AUTOSAR XML (schema 3.1.2)
package /Components/SWC_AirSysAir
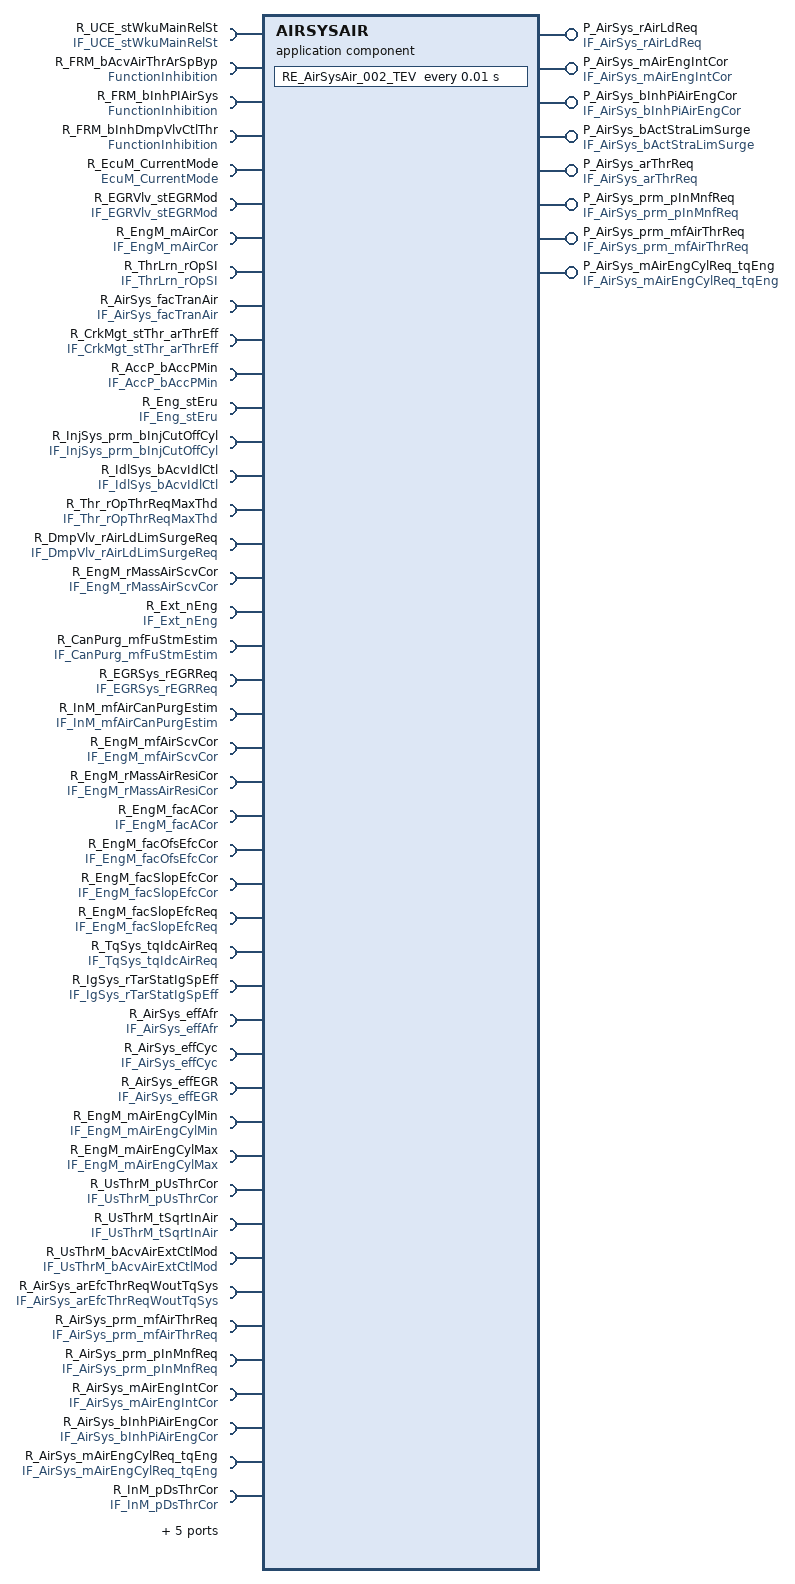
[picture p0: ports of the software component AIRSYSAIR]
  application software component type AIRSYSAIR  # AirSysAir
    4 x require port:
      R_UCE_stWkuMainRelSt: required-interface=IF_UCE_stWkuMainRelSt
      R_FRM_bAcvAirThrArSpByp: required-interface=FunctionInhibition
      R_FRM_bInhPIAirSys: required-interface=FunctionInhibition
      R_FRM_bInhDmpVlvCtlThr: required-interface=FunctionInhibition
    8 x provide port:
      P_AirSys_rAirLdReq: unqueued-sender-com-spec{data-element=AirSys_rAirLdReq, can-invalidate=false, init-value=ConstantValue}, provided-interface=IF_AirSys_rAirLdReq
      P_AirSys_mAirEngIntCor: unqueued-sender-com-spec{data-element=AirSys_mAirEngIntCor, can-invalidate=false, init-value=UInt32InitValue}, provided-interface=IF_AirSys_mAirEngIntCor
      P_AirSys_bInhPiAirEngCor: unqueued-sender-com-spec{data-element=AirSys_bInhPiAirEngCor, can-invalidate=false, init-value=BooleanInitValue}, provided-interface=IF_AirSys_bInhPiAirEngCor
      P_AirSys_bActStraLimSurge: unqueued-sender-com-spec{data-element=AirSys_bActStraLimSurge, can-invalidate=false, init-value=ConstantValue1}, provided-interface=IF_AirSys_bActStraLimSurge
      P_AirSys_arThrReq: unqueued-sender-com-spec{data-element=AirSys_arThrReq, can-invalidate=false, init-value=UInt16InitValue}, provided-interface=IF_AirSys_arThrReq
      P_AirSys_prm_pInMnfReq: unqueued-sender-com-spec{data-element=AirSys_prm_pInMnfReq, can-invalidate=false, init-value=rt_Array_UInt16_2InitValue}, provided-interface=IF_AirSys_prm_pInMnfReq
      P_AirSys_prm_mfAirThrReq: unqueued-sender-com-spec{data-element=AirSys_prm_mfAirThrReq, can-invalidate=false, init-value=rt_Array_UInt16_2InitValue3}, provided-interface=IF_AirSys_prm_mfAirThrReq
      P_AirSys_mAirEngCylReq_tqEng: unqueued-sender-com-spec{data-element=AirSys_mAirEngCylReq_tqEng, can-invalidate=false, init-value=UInt16InitValue5}, provided-interface=IF_AirSys_mAirEngCylReq_tqEng
    45 x require port:
      R_EcuM_CurrentMode: required-interface=EcuM_CurrentMode
      R_EGRVlv_stEGRMod: unqueued-receiver-com-spec{data-element=EGRVlv_stEGRMod, init-value=ConstantValue7, resync-time=0}, required-interface=IF_EGRVlv_stEGRMod
      R_EngM_mAirCor: unqueued-receiver-com-spec{data-element=EngM_mAirCor, init-value=ConstantValue9, resync-time=0}, required-interface=IF_EngM_mAirCor
      R_ThrLrn_rOpSI: unqueued-receiver-com-spec{data-element=ThrLrn_rOpSI, init-value=ConstantValue11, resync-time=0}, required-interface=IF_ThrLrn_rOpSI
      R_AirSys_facTranAir: unqueued-receiver-com-spec{data-element=AirSys_facTranAir, init-value=UInt16InitValue13, resync-time=0}, required-interface=IF_AirSys_facTranAir
      R_CrkMgt_stThr_arThrEff: unqueued-receiver-com-spec{data-element=CrkMgt_stThr_arThrEff, init-value=UInt8InitValue, resync-time=0}, required-interface=IF_CrkMgt_stThr_arThrEff
      R_AccP_bAccPMin: unqueued-receiver-com-spec{data-element=AccP_bAccPMin, init-value=BooleanInitValue15, resync-time=0}, required-interface=IF_AccP_bAccPMin
      R_Eng_stEru: unqueued-receiver-com-spec{data-element=Eng_stEru, init-value=ConstantValue17, resync-time=0}, required-interface=IF_Eng_stEru
      R_InjSys_prm_bInjCutOffCyl: unqueued-receiver-com-spec{data-element=InjSys_prm_bInjCutOffCyl, init-value=rt_Array_Boolean_6InitValue, resync-time=0}, required-interface=IF_InjSys_prm_bInjCutOffCyl
      R_IdlSys_bAcvIdlCtl: unqueued-receiver-com-spec{data-element=IdlSys_bAcvIdlCtl, init-value=ConstantValue19, resync-time=0}, required-interface=IF_IdlSys_bAcvIdlCtl
      R_Thr_rOpThrReqMaxThd: unqueued-receiver-com-spec{data-element=Thr_rOpThrReqMaxThd, init-value=UInt16InitValue21, resync-time=0}, required-interface=IF_Thr_rOpThrReqMaxThd
      R_DmpVlv_rAirLdLimSurgeReq: unqueued-receiver-com-spec{data-element=DmpVlv_rAirLdLimSurgeReq, init-value=UInt16InitValue23, resync-time=0}, required-interface=IF_DmpVlv_rAirLdLimSurgeReq
      R_EngM_rMassAirScvCor: unqueued-receiver-com-spec{data-element=EngM_rMassAirScvCor, init-value=UInt16InitValue25, resync-time=0}, required-interface=IF_EngM_rMassAirScvCor
      R_Ext_nEng: unqueued-receiver-com-spec{data-element=Ext_nEng, init-value=ConstantValue27, resync-time=0}, required-interface=IF_Ext_nEng
      R_CanPurg_mfFuStmEstim: unqueued-receiver-com-spec{data-element=CanPurg_mfFuStmEstim, init-value=UInt16InitValue29, resync-time=0}, required-interface=IF_CanPurg_mfFuStmEstim
      R_EGRSys_rEGRReq: unqueued-receiver-com-spec{data-element=EGRSys_rEGRReq, init-value=ConstantValue31, resync-time=0}, required-interface=IF_EGRSys_rEGRReq
      R_InM_mfAirCanPurgEstim: unqueued-receiver-com-spec{data-element=InM_mfAirCanPurgEstim, init-value=UInt16InitValue33, resync-time=0}, required-interface=IF_InM_mfAirCanPurgEstim
      R_EngM_mfAirScvCor: unqueued-receiver-com-spec{data-element=EngM_mfAirScvCor, init-value=UInt16InitValue35, resync-time=0}, required-interface=IF_EngM_mfAirScvCor
      R_EngM_rMassAirResiCor: unqueued-receiver-com-spec{data-element=EngM_rMassAirResiCor, init-value=UInt16InitValue37, resync-time=0}, required-interface=IF_EngM_rMassAirResiCor
      R_EngM_facACor: unqueued-receiver-com-spec{data-element=EngM_facACor, init-value=UInt8InitValue39, resync-time=0}, required-interface=IF_EngM_facACor
      R_EngM_facOfsEfcCor: unqueued-receiver-com-spec{data-element=EngM_facOfsEfcCor, init-value=UInt16InitValue41, resync-time=0}, required-interface=IF_EngM_facOfsEfcCor
      R_EngM_facSlopEfcCor: unqueued-receiver-com-spec{data-element=EngM_facSlopEfcCor, init-value=ConstantValue43, resync-time=0}, required-interface=IF_EngM_facSlopEfcCor
      R_EngM_facSlopEfcReq: unqueued-receiver-com-spec{data-element=EngM_facSlopEfcReq, init-value=UInt16InitValue45, resync-time=0}, required-interface=IF_EngM_facSlopEfcReq
      R_TqSys_tqIdcAirReq: unqueued-receiver-com-spec{data-element=TqSys_tqIdcAirReq, init-value=SInt16InitValue, resync-time=0}, required-interface=IF_TqSys_tqIdcAirReq
      R_IgSys_rTarStatIgSpEff: unqueued-receiver-com-spec{data-element=IgSys_rTarStatIgSpEff, init-value=UInt16InitValue47, resync-time=0}, required-interface=IF_IgSys_rTarStatIgSpEff
      R_AirSys_effAfr: unqueued-receiver-com-spec{data-element=AirSys_effAfr, init-value=UInt16InitValue49, resync-time=0}, required-interface=IF_AirSys_effAfr
      R_AirSys_effCyc: unqueued-receiver-com-spec{data-element=AirSys_effCyc, init-value=UInt16InitValue51, resync-time=0}, required-interface=IF_AirSys_effCyc
      R_AirSys_effEGR: unqueued-receiver-com-spec{data-element=AirSys_effEGR, init-value=UInt8InitValue53, resync-time=0}, required-interface=IF_AirSys_effEGR
      R_EngM_mAirEngCylMin: unqueued-receiver-com-spec{data-element=EngM_mAirEngCylMin, init-value=UInt32InitValue55, resync-time=0}, required-interface=IF_EngM_mAirEngCylMin
      R_EngM_mAirEngCylMax: unqueued-receiver-com-spec{data-element=EngM_mAirEngCylMax, init-value=UInt32InitValue57, resync-time=0}, required-interface=IF_EngM_mAirEngCylMax
      R_UsThrM_pUsThrCor: unqueued-receiver-com-spec{data-element=UsThrM_pUsThrCor, init-value=ConstantValue59, resync-time=0}, required-interface=IF_UsThrM_pUsThrCor
      R_UsThrM_tSqrtInAir: unqueued-receiver-com-spec{data-element=UsThrM_tSqrtInAir, init-value=UInt8InitValue61, resync-time=0}, required-interface=IF_UsThrM_tSqrtInAir
      R_UsThrM_bAcvAirExtCtlMod: unqueued-receiver-com-spec{data-element=UsThrM_bAcvAirExtCtlMod, init-value=BooleanInitValue63, resync-time=0}, required-interface=IF_UsThrM_bAcvAirExtCtlMod
      R_AirSys_arEfcThrReqWoutTqSys: unqueued-receiver-com-spec{data-element=AirSys_arEfcThrReqWoutTqSys, init-value=UInt32InitValue65, resync-time=0}, required-interface=IF_AirSys_arEfcThrReqWoutTqSys
      R_AirSys_prm_mfAirThrReq: unqueued-receiver-com-spec{data-element=AirSys_prm_mfAirThrReq, init-value=rt_Array_UInt16_2InitValue67, resync-time=0}, required-interface=IF_AirSys_prm_mfAirThrReq
      R_AirSys_prm_pInMnfReq: unqueued-receiver-com-spec{data-element=AirSys_prm_pInMnfReq, init-value=rt_Array_UInt16_2InitValue, resync-time=0}, required-interface=IF_AirSys_prm_pInMnfReq
      R_AirSys_mAirEngIntCor: unqueued-receiver-com-spec{data-element=AirSys_mAirEngIntCor, init-value=UInt32InitValue, resync-time=0}, required-interface=IF_AirSys_mAirEngIntCor
      R_AirSys_bInhPiAirEngCor: unqueued-receiver-com-spec{data-element=AirSys_bInhPiAirEngCor, init-value=BooleanInitValue, resync-time=0}, required-interface=IF_AirSys_bInhPiAirEngCor
      R_AirSys_mAirEngCylReq_tqEng: unqueued-receiver-com-spec{data-element=AirSys_mAirEngCylReq_tqEng, init-value=UInt16InitValue69, resync-time=0}, required-interface=IF_AirSys_mAirEngCylReq_tqEng
      R_InM_pDsThrCor: unqueued-receiver-com-spec{data-element=InM_pDsThrCor, init-value=ConstantValue71, resync-time=0}, required-interface=IF_InM_pDsThrCor
      R_Blby_mfFuStmCmpAirSys: unqueued-receiver-com-spec{data-element=Blby_mfFuStmCmpAirSys, init-value=SInt32InitValue, resync-time=0}, required-interface=IF_Blby_mfFuStmCmpAirSys
      R_DmpVlv_bAcvDmpVlv: unqueued-receiver-com-spec{data-element=DmpVlv_bAcvDmpVlv, init-value=BooleanInitValue73, resync-time=0}, required-interface=IF_DmpVlv_bAcvDmpVlv
      R_CoCha_bTqReqASR: unqueued-receiver-com-spec{data-element=CoCha_bTqReqASR, init-value=ConstantValue75, resync-time=0}, required-interface=IF_CoCha_bTqReqASR
      R_TqLimEM_tqIdcLimEM: unqueued-receiver-com-spec{data-element=TqLimEM_tqIdcLimEM, init-value=SInt16InitValue77, resync-time=0}, required-interface=IF_TqLimEM_tqIdcLimEM
      R_EngM_facOfsEfcReq: unqueued-receiver-com-spec{data-element=EngM_facOfsEfcReq, init-value=ConstantValue2, resync-time=0}, required-interface=IF_EngM_facOfsEfcReq
  56 x constant specification:
    BooleanInitValue
      value:
        boolean literal BooleanInitValue: type=DT_AirSys_bInhPiAirEngCor, value=false
    BooleanInitValue15
      value:
        boolean literal BooleanInitValue15: type=DT_AccP_bAccPMin, value=false
    BooleanInitValue63
      value:
        boolean literal BooleanInitValue63: type=DT_UsThrM_bAcvAirExtCtlMod, value=false
    BooleanInitValue73
      value:
        boolean literal BooleanInitValue73: type=DT_DmpVlv_bAcvDmpVlv, value=false
    ConstantValue
      value:
        integer literal ConstantValue: type=DT_AirSys_rAirLdReq, value=0
    ConstantValue1
      value:
        boolean literal ConstantValue1: type=DT_AirSys_bActStraLimSurge, value=false
    ConstantValue11
      value:
        integer literal ConstantValue11: type=DT_ThrLrn_rOpSI, value=0
    ConstantValue17
      value:
        integer literal ConstantValue17: type=DT_Eng_stEru, value=1
    ConstantValue19
      value:
        boolean literal ConstantValue19: type=DT_IdlSys_bAcvIdlCtl, value=false
    ConstantValue2
      value:
        integer literal ConstantValue2: type=DT_EngM_facOfsEfcReq, value=0
    ConstantValue27
      value:
        integer literal ConstantValue27: type=DT_Ext_nEng, value=0
    ConstantValue31
      value:
        integer literal ConstantValue31: type=DT_EGRSys_rEGRReq, value=0
    ConstantValue43
      value:
        integer literal ConstantValue43: type=DT_EngM_facSlopEfcCor, value=0
    ConstantValue59
      value:
        integer literal ConstantValue59: type=DT_UsThrM_pUsThrCor, value=0
    ConstantValue7
      value:
        integer literal ConstantValue7: type=DT_EGRVlv_stEGRMod, value=1
    ConstantValue71
      value:
        integer literal ConstantValue71: type=DT_InM_pDsThrCor, value=0
    ConstantValue75
      value:
        boolean literal ConstantValue75: type=DT_CoCha_bTqReqASR, value=false
    ConstantValue9
      value:
        integer literal ConstantValue9: type=DT_EngM_mAirCor, value=0
    InitValue_Boolean_0
      value:
        boolean literal InitValue_Boolean_0: type=DT_AirSys_bActStraLimSurgeDmpSw_irv, value=false
    InitValue_UInt16_0
      value:
        integer literal InitValue_UInt16_0: type=DT_AirSys_prm_mAirCylReq_01_irv, value=0
    InitValue_UInt16_079
      value:
        integer literal InitValue_UInt16_079: type=DT_AirSys_mAirEngCorReq_irv, value=0
    InitValue_UInt16_081
      value:
        integer literal InitValue_UInt16_081: type=DT_AirSys_arEfcThrReqTqSys_irv, value=0
    InitValue_UInt16_083
      value:
        integer literal InitValue_UInt16_083: type=DT_AirSys_prm_mAirCylReq_02_irv, value=0
    InitValue_UInt16_085
      value:
        integer literal InitValue_UInt16_085: type=DT_AirSys_rAirPresReq_irv, value=0
    InitValue_UInt16_087
      value:
        integer literal InitValue_UInt16_087: type=DT_AirSys_tiDlyAftEgrFoul_irv, value=0
    rt_Array_Boolean_6InitValue
      value:
        array specification rt_Array_Boolean_6InitValue: type=rt_Array_Boolean_6_m0
          6 x boolean literal, all with type=DT_InjSys_prm_bInjCutOffCyl, value=false:
            Boolean_{1..6}
    rt_Array_UInt16_2InitValue
      value:
        array specification rt_Array_UInt16_2InitValue: type=rt_Array_UInt16_2_m2
          integer literal UInt16_1: type=DT_AirSys_prm_pInMnfReq, value=0
          integer literal UInt16_2: type=DT_AirSys_prm_pInMnfReq, value=0
    rt_Array_UInt16_2InitValue3
      value:
        array specification rt_Array_UInt16_2InitValue3: type=rt_Array_UInt16_2_m1
          integer literal UInt16_1: type=DT_AirSys_prm_mfAirThrReq, value=0
          integer literal UInt16_2: type=DT_AirSys_prm_mfAirThrReq, value=0
    rt_Array_UInt16_2InitValue67
      value:
        array specification rt_Array_UInt16_2InitValue67: type=rt_Array_UInt16_2_m1
          integer literal UInt16_1: type=DT_AirSys_prm_mfAirThrReq, value=0
          integer literal UInt16_2: type=DT_AirSys_prm_mfAirThrReq, value=0
    SInt16InitValue
      value:
        integer literal SInt16InitValue: type=DT_TqSys_tqIdcAirReq, value=-32000
    SInt16InitValue77
      value:
        integer literal SInt16InitValue77: type=DT_TqLimEM_tqIdcLimEM, value=0
    SInt32InitValue
      value:
        integer literal SInt32InitValue: type=DT_Blby_mfFuStmCmpAirSys, value=0
    UInt16InitValue
      value:
        integer literal UInt16InitValue: type=DT_AirSys_arThrReq, value=0
    UInt16InitValue13
      value:
        integer literal UInt16InitValue13: type=DT_AirSys_facTranAir, value=0
    UInt16InitValue21
      value:
        integer literal UInt16InitValue21: type=DT_Thr_rOpThrReqMaxThd, value=0
    UInt16InitValue23
      value:
        integer literal UInt16InitValue23: type=DT_DmpVlv_rAirLdLimSurgeReq, value=0
    UInt16InitValue25
      value:
        integer literal UInt16InitValue25: type=DT_EngM_rMassAirScvCor, value=0
    UInt16InitValue29
      value:
        integer literal UInt16InitValue29: type=DT_CanPurg_mfFuStmEstim, value=0
    UInt16InitValue33
      value:
        integer literal UInt16InitValue33: type=DT_InM_mfAirCanPurgEstim, value=0
    UInt16InitValue35
      value:
        integer literal UInt16InitValue35: type=DT_EngM_mfAirScvCor, value=0
    UInt16InitValue37
      value:
        integer literal UInt16InitValue37: type=DT_EngM_rMassAirResiCor, value=0
    UInt16InitValue41
      value:
        integer literal UInt16InitValue41: type=DT_EngM_facOfsEfcCor, value=0
    UInt16InitValue45
      value:
        integer literal UInt16InitValue45: type=DT_EngM_facSlopEfcReq, value=0
    UInt16InitValue47
      value:
        integer literal UInt16InitValue47: type=DT_IgSys_rTarStatIgSpEff, value=1024
    UInt16InitValue49
      value:
        integer literal UInt16InitValue49: type=DT_AirSys_effAfr, value=0
    UInt16InitValue5
      value:
        integer literal UInt16InitValue5: type=DT_AirSys_mAirEngCylReq_tqEng, value=0
    UInt16InitValue51
      value:
        integer literal UInt16InitValue51: type=DT_AirSys_effCyc, value=0
    UInt16InitValue69
      value:
        integer literal UInt16InitValue69: type=DT_AirSys_mAirEngCylReq_tqEng, value=0
    UInt32InitValue
      value:
        integer literal UInt32InitValue: type=DT_AirSys_mAirEngIntCor, value=2147456160
    UInt32InitValue55
      value:
        integer literal UInt32InitValue55: type=DT_EngM_mAirEngCylMin, value=0
    UInt32InitValue57
      value:
        integer literal UInt32InitValue57: type=DT_EngM_mAirEngCylMax, value=0
    UInt32InitValue65
      value:
        integer literal UInt32InitValue65: type=DT_AirSys_arEfcThrReqWoutTqSys, value=0
    UInt8InitValue
      value:
        integer literal UInt8InitValue: type=DT_CrkMgt_stThr_arThrEff, value=1
    UInt8InitValue39
      value:
        integer literal UInt8InitValue39: type=DT_EngM_facACor, value=0
    UInt8InitValue53
      value:
        integer literal UInt8InitValue53: type=DT_AirSys_effEGR, value=0
    UInt8InitValue61
      value:
        integer literal UInt8InitValue61: type=DT_UsThrM_tSqrtInAir, value=120
  internal behavior IB_AirSysAir: component=AIRSYSAIR
    timing event EV_AirSysAir_002_TEV: mode-dependency=dependent-on-mode=[R_UCE_stWkuMainRelSt.RCD_stWkuMainRelSt.PreMainWakeUp, R_UCE_stWkuMainRelSt.RCD_stWkuMainRelSt.PostMainWakeUp, R_UCE_stWkuMainRelSt.RCD_stWkuMainRelSt.Invalid], start-on-event=RE_AirSysAir_002_TEV, period=0.01
    mode switch event EV_AirSysAir_001_MSE: start-on-event=RE_AirSysAir_001_MSE, activation=ENTRY, mode=R_EcuM_CurrentMode.currentMode.RUN
    5 x timing event, all with mode-dependency=dependent-on-mode=[R_UCE_stWkuMainRelSt.RCD_stWkuMainRelSt.PreMainWakeUp, R_UCE_stWkuMainRelSt.RCD_stWkuMainRelSt.PostMainWakeUp, R_UCE_stWkuMainRelSt.RCD_stWkuMainRelSt.Invalid], period=0.01:
      EV_AirSysAir_{004..006}_TEV: start-on-event=RE_AirSysAir_{004..006}_TEV
      EV_AirSysAir_003_TEV: start-on-event=RE_AirSysAir_003_TEV
      EV_AirSysAir_007_TEV: start-on-event=RE_AirSysAir_007_TEV
    7 x inter runnable variable, all with sw-calibration-access=READ-WRITE, communication-approach=EXPLICIT:
      AirSys_arEfcThrReqTqSys_irv: type=DT_AirSys_arEfcThrReqTqSys_irv, init-value=InitValue_UInt16_081
      AirSys_tiDlyAftEgrFoul_irv: type=DT_AirSys_tiDlyAftEgrFoul_irv, init-value=InitValue_UInt16_087
      AirSys_rAirPresReq_irv: type=DT_AirSys_rAirPresReq_irv, init-value=InitValue_UInt16_085
      AirSys_prm_mAirCylReq_01_irv: type=DT_AirSys_prm_mAirCylReq_01_irv, init-value=InitValue_UInt16_0
      AirSys_prm_mAirCylReq_02_irv: type=DT_AirSys_prm_mAirCylReq_02_irv, init-value=InitValue_UInt16_083
      AirSys_bActStraLimSurgeDmpSw_irv: type=DT_AirSys_bActStraLimSurgeDmpSw_irv, init-value=InitValue_Boolean_0
      AirSys_mAirEngCorReq_irv: type=DT_AirSys_mAirEngCorReq_irv, init-value=InitValue_UInt16_079
    7 x runnable:
      RE_AirSysAir_005_TEV: read-variable=[AirSys_prm_mAirCylReq_02_irv, AirSys_prm_mAirCylReq_01_irv]
        6 x data receive point:
          dr_EngM_rMassAirResiCor: data-element=R_EngM_rMassAirResiCor.EngM_rMassAirResiCor
          dr_EngM_facOfsEfcCor: data-element=R_EngM_facOfsEfcCor.EngM_facOfsEfcCor
          dr_EngM_facACor: data-element=R_EngM_facACor.EngM_facACor
          dr_EngM_facOfsEfcReq: data-element=R_EngM_facOfsEfcReq.EngM_facOfsEfcReq
          dr_EngM_facSlopEfcReq: data-element=R_EngM_facSlopEfcReq.EngM_facSlopEfcReq
          dr_EngM_facSlopEfcCor: data-element=R_EngM_facSlopEfcCor.EngM_facSlopEfcCor
        data send point ds_AirSys_prm_pInMnfReq: data-element=P_AirSys_prm_pInMnfReq.AirSys_prm_pInMnfReq
      RE_AirSysAir_006_TEV: read-variable=[AirSys_rAirPresReq_irv, AirSys_bActStraLimSurgeDmpSw_irv], written-variable=[AirSys_rAirPresReq_irv, AirSys_arEfcThrReqTqSys_irv]
        10 x data receive point:
          dr_TqLimEM_tqIdcLimEM: data-element=R_TqLimEM_tqIdcLimEM.TqLimEM_tqIdcLimEM
          dr_UsThrM_pUsThrCor: data-element=R_UsThrM_pUsThrCor.UsThrM_pUsThrCor
          dr_InM_pDsThrCor: data-element=R_InM_pDsThrCor.InM_pDsThrCor
          dr_UsThrM_bAcvAirExtCtlMod: data-element=R_UsThrM_bAcvAirExtCtlMod.UsThrM_bAcvAirExtCtlMod
          dr_DmpVlv_bAcvDmpVlv: data-element=R_DmpVlv_bAcvDmpVlv.DmpVlv_bAcvDmpVlv
          dr_UsThrM_tSqrtInAir: data-element=R_UsThrM_tSqrtInAir.UsThrM_tSqrtInAir
          dr_CoCha_bTqReqASR: data-element=R_CoCha_bTqReqASR.CoCha_bTqReqASR
          dr_Ext_nEng: data-element=R_Ext_nEng.Ext_nEng
          dr_AirSys_prm_mfAirThrReq: data-element=R_AirSys_prm_mfAirThrReq.AirSys_prm_mfAirThrReq
          dr_AirSys_prm_pInMnfReq: data-element=R_AirSys_prm_pInMnfReq.AirSys_prm_pInMnfReq
        data send point ds_AirSys_bActStraLimSurge: data-element=P_AirSys_bActStraLimSurge.AirSys_bActStraLimSurge
        sync call ssp_FRM_bInhDmpVlvCtlThr: operation=R_FRM_bInhDmpVlvCtlThr.GetFunctionPermission
      RE_AirSysAir_002_TEV
        7 x data receive point:
          dr_TqSys_tqIdcAirReq: data-element=R_TqSys_tqIdcAirReq.TqSys_tqIdcAirReq
          dr_EngM_mAirEngCylMin: data-element=R_EngM_mAirEngCylMin.EngM_mAirEngCylMin
          dr_IgSys_rTarStatIgSpEff: data-element=R_IgSys_rTarStatIgSpEff.IgSys_rTarStatIgSpEff
          dr_AirSys_effAfr: data-element=R_AirSys_effAfr.AirSys_effAfr
          dr_AirSys_effCyc: data-element=R_AirSys_effCyc.AirSys_effCyc
          dr_AirSys_effEGR: data-element=R_AirSys_effEGR.AirSys_effEGR
          dr_EngM_mAirEngCylMax: data-element=R_EngM_mAirEngCylMax.EngM_mAirEngCylMax
        data send point ds_AirSys_mAirEngCylReq_tqEng: data-element=P_AirSys_mAirEngCylReq_tqEng.AirSys_mAirEngCylReq_tqEng
        data send point ds_AirSys_rAirLdReq: data-element=P_AirSys_rAirLdReq.AirSys_rAirLdReq
      RE_AirSysAir_001_MSE: written-variable=[AirSys_prm_mAirCylReq_01_irv, AirSys_bActStraLimSurgeDmpSw_irv, AirSys_mAirEngCorReq_irv, AirSys_tiDlyAftEgrFoul_irv, AirSys_arEfcThrReqTqSys_irv, AirSys_prm_mAirCylReq_02_irv, AirSys_rAirPresReq_irv]
        8 x data send point:
          ds_AirSys_rAirLdReq: data-element=P_AirSys_rAirLdReq.AirSys_rAirLdReq
          ds_AirSys_prm_pInMnfReq: data-element=P_AirSys_prm_pInMnfReq.AirSys_prm_pInMnfReq
          ds_AirSys_mAirEngIntCor: data-element=P_AirSys_mAirEngIntCor.AirSys_mAirEngIntCor
          ds_AirSys_arThrReq: data-element=P_AirSys_arThrReq.AirSys_arThrReq
          ds_AirSys_bInhPiAirEngCor: data-element=P_AirSys_bInhPiAirEngCor.AirSys_bInhPiAirEngCor
          ds_AirSys_mAirEngCylReq_tqEng: data-element=P_AirSys_mAirEngCylReq_tqEng.AirSys_mAirEngCylReq_tqEng
          ds_AirSys_bActStraLimSurge: data-element=P_AirSys_bActStraLimSurge.AirSys_bActStraLimSurge
          ds_AirSys_prm_mfAirThrReq: data-element=P_AirSys_prm_mfAirThrReq.AirSys_prm_mfAirThrReq
      RE_AirSysAir_003_TEV: read-variable=AirSys_tiDlyAftEgrFoul_irv, written-variable=[AirSys_tiDlyAftEgrFoul_irv, AirSys_mAirEngCorReq_irv, AirSys_bActStraLimSurgeDmpSw_irv]
        16 x data receive point:
          dr_AirSys_facTranAir: data-element=R_AirSys_facTranAir.AirSys_facTranAir
          dr_AirSys_mAirEngIntCor: data-element=R_AirSys_mAirEngIntCor.AirSys_mAirEngIntCor
          dr_AirSys_bInhPiAirEngCor: data-element=R_AirSys_bInhPiAirEngCor.AirSys_bInhPiAirEngCor
          dr_Eng_stEru: data-element=R_Eng_stEru.Eng_stEru
          dr_DmpVlv_rAirLdLimSurgeReq: data-element=R_DmpVlv_rAirLdLimSurgeReq.DmpVlv_rAirLdLimSurgeReq
          dr_EngM_rMassAirScvCor: data-element=R_EngM_rMassAirScvCor.EngM_rMassAirScvCor
          dr_InjSys_prm_bInjCutOffCyl: data-element=R_InjSys_prm_bInjCutOffCyl.InjSys_prm_bInjCutOffCyl
          dr_AccP_bAccPMin: data-element=R_AccP_bAccPMin.AccP_bAccPMin
          dr_IdlSys_bAcvIdlCtl: data-element=R_IdlSys_bAcvIdlCtl.IdlSys_bAcvIdlCtl
          dr_CrkMgt_stThr_arThrEff: data-element=R_CrkMgt_stThr_arThrEff.CrkMgt_stThr_arThrEff
          dr_AirSys_mAirEngCylReq_tqEng: data-element=R_AirSys_mAirEngCylReq_tqEng.AirSys_mAirEngCylReq_tqEng
          dr_EngM_mAirCor: data-element=R_EngM_mAirCor.EngM_mAirCor
          dr_EGRVlv_stEGRMod: data-element=R_EGRVlv_stEGRMod.EGRVlv_stEGRMod
          dr_Ext_nEng: data-element=R_Ext_nEng.Ext_nEng
          dr_ThrLrn_rOpSI: data-element=R_ThrLrn_rOpSI.ThrLrn_rOpSI
          dr_Thr_rOpThrReqMaxThd: data-element=R_Thr_rOpThrReqMaxThd.Thr_rOpThrReqMaxThd
        data send point ds_AirSys_bInhPiAirEngCor: data-element=P_AirSys_bInhPiAirEngCor.AirSys_bInhPiAirEngCor
        data send point ds_AirSys_mAirEngIntCor: data-element=P_AirSys_mAirEngIntCor.AirSys_mAirEngIntCor
        sync call ssp_FRM_bInhPIAirSys: operation=R_FRM_bInhPIAirSys.GetFunctionPermission
      RE_AirSysAir_007_TEV: read-variable=AirSys_arEfcThrReqTqSys_irv
        data receive point dr_CrkMgt_stThr_arThrEff: data-element=R_CrkMgt_stThr_arThrEff.CrkMgt_stThr_arThrEff
        data receive point dr_AirSys_arEfcThrReqWoutTqSys: data-element=R_AirSys_arEfcThrReqWoutTqSys.AirSys_arEfcThrReqWoutTqSys
        data receive point dr_AirSys_facTranAir: data-element=R_AirSys_facTranAir.AirSys_facTranAir
        data send point ds_AirSys_arThrReq: data-element=P_AirSys_arThrReq.AirSys_arThrReq
        sync call ssp_FRM_bAcvAirThrArSpByp: operation=R_FRM_bAcvAirThrArSpByp.GetFunctionPermission
      RE_AirSysAir_004_TEV: read-variable=AirSys_mAirEngCorReq_irv, written-variable=[AirSys_prm_mAirCylReq_02_irv, AirSys_prm_mAirCylReq_01_irv]
        8 x data receive point:
          dr_EngM_mfAirScvCor: data-element=R_EngM_mfAirScvCor.EngM_mfAirScvCor
          dr_EGRSys_rEGRReq: data-element=R_EGRSys_rEGRReq.EGRSys_rEGRReq
          dr_InM_mfAirCanPurgEstim: data-element=R_InM_mfAirCanPurgEstim.InM_mfAirCanPurgEstim
          dr_Ext_nEng: data-element=R_Ext_nEng.Ext_nEng
          dr_EngM_rMassAirResiCor: data-element=R_EngM_rMassAirResiCor.EngM_rMassAirResiCor
          dr_CanPurg_mfFuStmEstim: data-element=R_CanPurg_mfFuStmEstim.CanPurg_mfFuStmEstim
          dr_AirSys_mAirEngCylReq_tqEng: data-element=R_AirSys_mAirEngCylReq_tqEng.AirSys_mAirEngCylReq_tqEng
          dr_Blby_mfFuStmCmpAirSys: data-element=R_Blby_mfFuStmCmpAirSys.Blby_mfFuStmCmpAirSys
        data send point ds_AirSys_prm_mfAirThrReq: data-element=P_AirSys_prm_mfAirThrReq.AirSys_prm_mfAirThrReq
  swc implementation Imp_AirSysAir: code-generator=Real-Time Workshop Embedded Coder 5.5 (R2010a) 25-Jan-2010, programming-language=C, behavior=IB_AirSysAir
    code-descriptors:
      code CodeDescriptor: type=SRC
        10 x xfile:
          AirSysAir_private_h: url=AirSysAir_private.h
          AirSysAir_c: url=AirSysAir.c
          AirSysAir_data_c: url=AirSysAir_data.c
          AirSysAir_Version_h: url=AirSysAir_Version.h
          AirSysAir_import_h: url=AirSysAir_import.h
          AirSysAir_Def_c: url=AirSysAir_Def.c
          AirSysAir_Version_c: url=AirSysAir_Version.c
          AirSysAir_MemMap_h: url=AirSysAir_MemMap.h
          AirSysAir_types_h: url=AirSysAir_types.h
          AirSysAir_h: url=AirSysAir.h
package /Components/SWC_AirSysAir/AirSysAir_IRVDatatypes
  boolean type DT_AirSys_bActStraLimSurgeDmpSw_irv: base-type=boolean
  6 x integer type, all with base-type=uint16, lower-limit=0, upper-limit=65535:
    DT_AirSys_arEfcThrReqTqSys_irv
    DT_AirSys_mAirEngCorReq_irv
    DT_AirSys_prm_mAirCylReq_01_irv
    DT_AirSys_prm_mAirCylReq_02_irv
    DT_AirSys_rAirPresReq_irv
    DT_AirSys_tiDlyAftEgrFoul_irv
